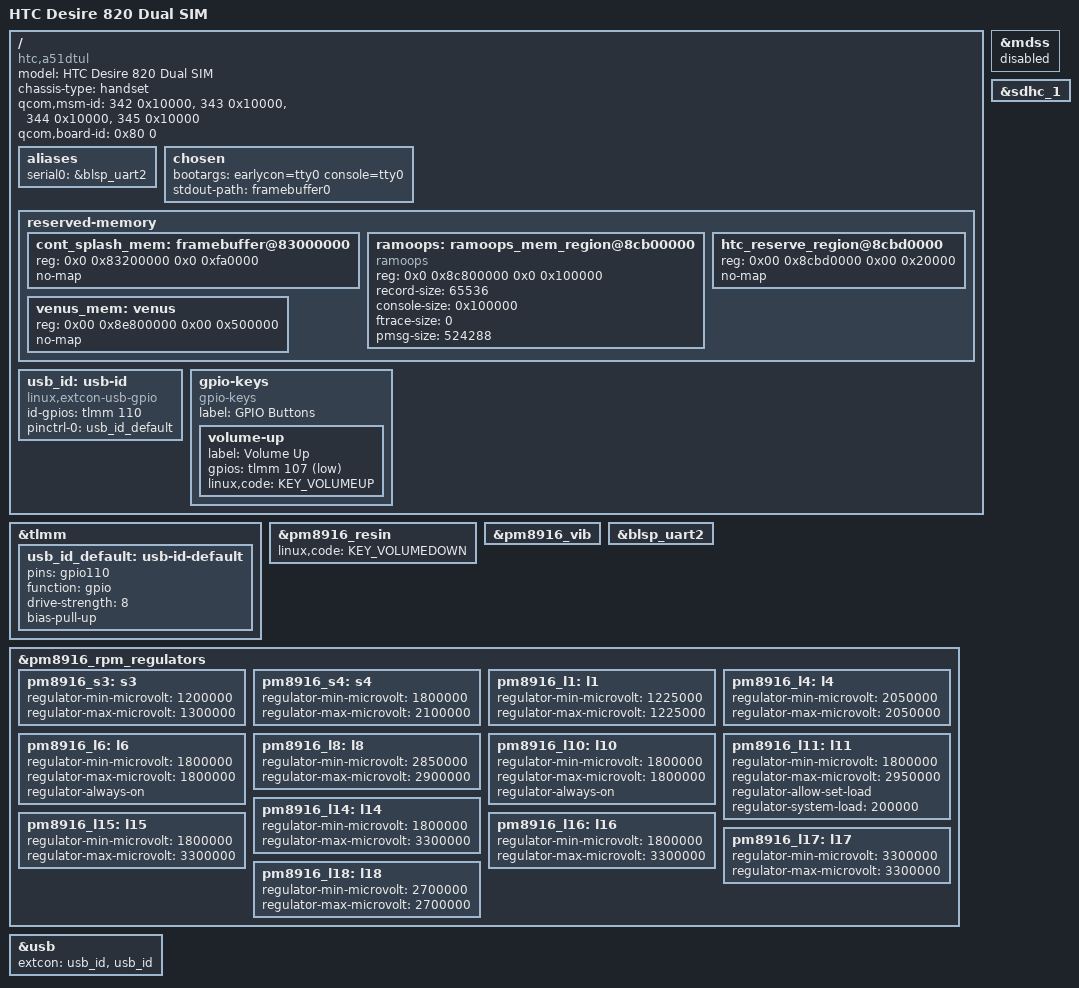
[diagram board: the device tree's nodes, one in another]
// SPDX-License-Identifier: GPL-2.0-only

/dts-v1/;

#include "msm8939-pm8916.dtsi"

#include <dt-bindings/gpio/gpio.h>
#include <dt-bindings/iio/qcom,spmi-vadc.h>
#include <dt-bindings/input/input.h>
#include <dt-bindings/leds/common.h>
#include <dt-bindings/pinctrl/qcom,pmic-mpp.h>

/ {
	model = "HTC Desire 820 Dual SIM";
	compatible = "htc,a51dtul", "qcom,msm8939";
	chassis-type = "handset";
	qcom,msm-id = <342 0x10000>, <343 0x10000>, <344 0x10000>, <345 0x10000>;
	qcom,board-id = <0x80 0>;

	aliases {
		serial0 = &blsp_uart2;
	};

	chosen {
		bootargs = "earlycon=tty0 console=tty0";
		stdout-path = "framebuffer0";

		#address-cells = <2>;
		#size-cells = <2>;
		ranges;
	};
	
	reserved-memory {
		#address-cells = <2>;
		#size-cells = <2>;
		ranges;

		cont_splash_mem: framebuffer@83000000 {
			reg = <0x0 0x83200000 0x0 0xfa0000>;
			no-map;
        };

		ramoops: ramoops_mem_region@8cb00000 {
			compatible = "ramoops";
			reg = <0x0 0x8c800000 0x0 0x100000>;

			record-size = <65536>;
			console-size = <0x100000>;
			ftrace-size = <0>;
			pmsg-size = <524288>;
		};

		htc_reserve_region@8cbd0000 {
			reg = <0x00 0x8cbd0000 0x00 0x20000>;
			no-map;
		};

		venus_mem: venus {
			status = "okay";
			reg = <0x00 0x8e800000 0x00 0x500000>;
			no-map;
		};
	};
	
	usb_id: usb-id {
		compatible = "linux,extcon-usb-gpio";
		id-gpios = <&tlmm 110 GPIO_ACTIVE_HIGH>;
		pinctrl-names = "default";
		pinctrl-0 = <&usb_id_default>;
	};

	
	gpio-keys {
		compatible = "gpio-keys";

		pinctrl-names = "default";

		label = "GPIO Buttons";

		volume-up {
			label = "Volume Up";
			gpios = <&tlmm 107 GPIO_ACTIVE_LOW>;
			linux,code = <KEY_VOLUMEUP>;
		};
	};
};


&mdss {
	status = "disabled";
};

&tlmm {
	usb_id_default: usb-id-default {
		pins = "gpio110";
		function = "gpio";

		drive-strength = <8>;
		bias-pull-up;
	};
};


&pm8916_resin {
	status = "okay";
	linux,code = <KEY_VOLUMEDOWN>;
};


&pm8916_vib {
	status = "okay";
};

&blsp_uart2 {
	status = "okay";
};

&pm8916_rpm_regulators {
	pm8916_s3: s3 { // ok
		regulator-min-microvolt = <1200000>;
		regulator-max-microvolt = <1300000>;
	};

	pm8916_s4: s4 { // ok
		regulator-min-microvolt = <1800000>;
		regulator-max-microvolt = <2100000>;
	};

	pm8916_l1: l1 { // ok
		regulator-min-microvolt = <1225000>;
		regulator-max-microvolt = <1225000>;
	};

	pm8916_l4: l4 { // ok
		regulator-min-microvolt = <2050000>;
		regulator-max-microvolt = <2050000>;
	};

	pm8916_l6: l6 { // ok
		regulator-min-microvolt = <1800000>;
		regulator-max-microvolt = <1800000>;
		regulator-always-on;
	};

	pm8916_l8: l8 { // ok
		regulator-min-microvolt = <2850000>;
		regulator-max-microvolt = <2900000>;
	};

	pm8916_l10: l10 { // ok, didn't originally match downstream
		regulator-min-microvolt = <1800000>;
		regulator-max-microvolt = <1800000>;
		regulator-always-on; /* comment from downstream: V_AUD_1V8 need always on as audio request */
	};

	pm8916_l11: l11 { // ok!!
		regulator-min-microvolt = <1800000>;
		regulator-max-microvolt = <2950000>;
		regulator-allow-set-load;
		regulator-system-load = <200000>;
	};

	pm8916_l14: l14 { // ok
		regulator-min-microvolt = <1800000>;
		regulator-max-microvolt = <3300000>;
	};
	pm8916_l15: l15 { // ok
		regulator-min-microvolt = <1800000>;
		regulator-max-microvolt = <3300000>;
	};
	pm8916_l16: l16 { // ok
		regulator-min-microvolt = <1800000>;
		regulator-max-microvolt = <3300000>;
	};
	pm8916_l17: l17 { 
		regulator-min-microvolt = <3300000>;
		regulator-max-microvolt = <3300000>;
	};
	pm8916_l18: l18 { // ok
		regulator-min-microvolt = <2700000>;
		regulator-max-microvolt = <2700000>;
	};
};

&sdhc_1 {
	status = "okay";
};



&usb {
	status = "okay";
	extcon = <&usb_id>, <&usb_id>;
};
